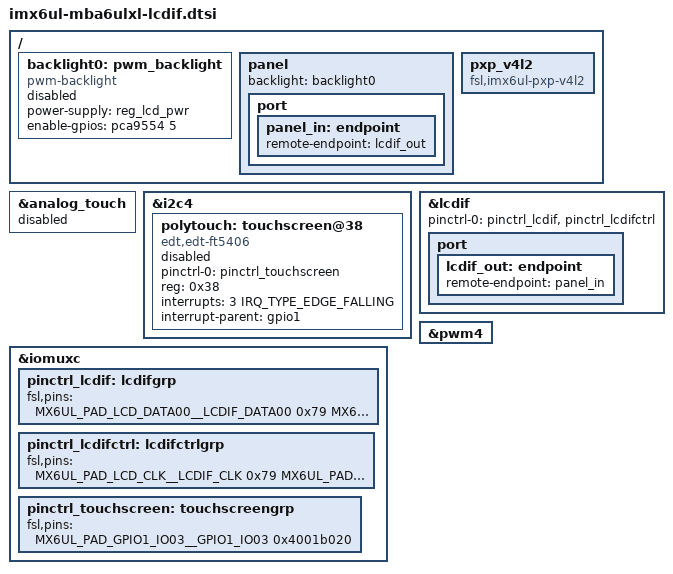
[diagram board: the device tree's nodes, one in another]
// SPDX-License-Identifier: (GPL-2.0-or-later OR MIT)
/*
 * Copyright 2016-2018 TQ Systems GmbH
 * Author: Marco Felsch
 *         Markus Niebel <Markus.Niebel@tq-group.com>
 */

/ {
	backlight0: pwm_backlight {
		compatible = "pwm-backlight";
		power-supply = <&reg_lcd_pwr>;
		enable-gpios = <&pca9554 5 GPIO_ACTIVE_HIGH>;
		status = "disabled";
	};

	panel: panel {
		backlight = <&backlight0>;

		port {
			panel_in: endpoint {
				remote-endpoint = <&lcdif_out>;
			};
		};
	};

	pxp_v4l2 {
		compatible = "fsl,imx6ul-pxp-v4l2", "fsl,imx6sx-pxp-v4l2", "fsl,imx6sl-pxp-v4l2";
		status = "okay";
	};
};

&analog_touch {
	status = "disabled";
};

&i2c4 {
	polytouch: touchscreen@38 {
		pinctrl-names = "default";
		pinctrl-0 = <&pinctrl_touchscreen>;
		compatible = "edt,edt-ft5406", "edt,edt-ft5x06";
		reg = <0x38>;
		interrupts = <3 IRQ_TYPE_EDGE_FALLING>;
		interrupt-parent = <&gpio1>;
		status = "disabled";
	};
};

&iomuxc {
	pinctrl_lcdif: lcdifgrp {
		fsl,pins = <
			MX6UL_PAD_LCD_DATA00__LCDIF_DATA00	0x79
			MX6UL_PAD_LCD_DATA01__LCDIF_DATA01	0x79
			MX6UL_PAD_LCD_DATA02__LCDIF_DATA02	0x79
			MX6UL_PAD_LCD_DATA03__LCDIF_DATA03	0x79
			MX6UL_PAD_LCD_DATA04__LCDIF_DATA04	0x79
			MX6UL_PAD_LCD_DATA05__LCDIF_DATA05	0x79
			MX6UL_PAD_LCD_DATA06__LCDIF_DATA06	0x79
			MX6UL_PAD_LCD_DATA07__LCDIF_DATA07	0x79
			MX6UL_PAD_LCD_DATA08__LCDIF_DATA08	0x79
			MX6UL_PAD_LCD_DATA09__LCDIF_DATA09	0x79
			MX6UL_PAD_LCD_DATA10__LCDIF_DATA10	0x79
			MX6UL_PAD_LCD_DATA11__LCDIF_DATA11	0x79
			MX6UL_PAD_LCD_DATA12__LCDIF_DATA12	0x79
			MX6UL_PAD_LCD_DATA13__LCDIF_DATA13	0x79
			MX6UL_PAD_LCD_DATA14__LCDIF_DATA14	0x79
			MX6UL_PAD_LCD_DATA15__LCDIF_DATA15	0x79
			MX6UL_PAD_LCD_DATA16__LCDIF_DATA16	0x79
			MX6UL_PAD_LCD_DATA17__LCDIF_DATA17	0x79
			MX6UL_PAD_LCD_DATA18__LCDIF_DATA18	0x79
			MX6UL_PAD_LCD_DATA19__LCDIF_DATA19	0x79
			MX6UL_PAD_LCD_DATA20__LCDIF_DATA20	0x79
			MX6UL_PAD_LCD_DATA21__LCDIF_DATA21	0x79
			MX6UL_PAD_LCD_DATA22__LCDIF_DATA22	0x79
			MX6UL_PAD_LCD_DATA23__LCDIF_DATA23	0x79
		>;
	};

	pinctrl_lcdifctrl: lcdifctrlgrp {
		fsl,pins = <
			MX6UL_PAD_LCD_CLK__LCDIF_CLK		0x79
			MX6UL_PAD_LCD_ENABLE__LCDIF_ENABLE	0x79
			MX6UL_PAD_LCD_HSYNC__LCDIF_HSYNC	0x79
			MX6UL_PAD_LCD_VSYNC__LCDIF_VSYNC	0x79
		>;
	};

	pinctrl_touchscreen: touchscreengrp {
		fsl,pins = <
			MX6UL_PAD_GPIO1_IO03__GPIO1_IO03	0x4001b020
		>;
	};
};

&lcdif {
	pinctrl-names = "default";
	pinctrl-0 = <&pinctrl_lcdif>, <&pinctrl_lcdifctrl>;

	port {
		lcdif_out: endpoint {
			remote-endpoint = <&panel_in>;
		};
	};
};

&pwm4 {
	status = "okay";
};
